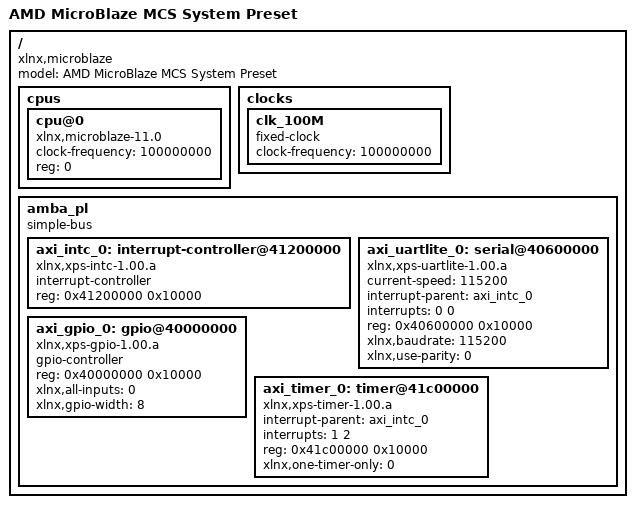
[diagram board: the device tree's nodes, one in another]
/dts-v1/;

/ {
    #address-cells = <1>;
    #size-cells = <1>;
    model = "AMD MicroBlaze MCS System Preset";
    compatible = "xlnx,microblaze";

    cpus {
        #address-cells = <1>;
        #size-cells = <0>;
        cpu@0 {
            clock-frequency = <100000000>;
            compatible = "xlnx,microblaze-11.0";
            device_type = "cpu";
            reg = <0>;
        };
    };

    clocks {
        clk_100M: clk_100M {
            #clock-cells = <0>;
            compatible = "fixed-clock";
            clock-frequency = <100000000>;
        };
    };

    amba_pl: amba_pl {
        #address-cells = <1>;
        #size-cells = <1>;
        compatible = "simple-bus";
        ranges;

        axi_intc_0: interrupt-controller@41200000 {
            #interrupt-cells = <2>;
            compatible = "xlnx,xps-intc-1.00.a";
            interrupt-controller;
            reg = <0x41200000 0x10000>;
        };

        axi_uartlite_0: serial@40600000 {
            compatible = "xlnx,xps-uartlite-1.00.a";
            current-speed = <115200>;
            device_type = "serial";
            interrupt-parent = <&axi_intc_0>;
            interrupts = <0 0>;
            reg = <0x40600000 0x10000>;
            xlnx,baudrate = <115200>;
            xlnx,use-parity = <0>;
        };

        axi_gpio_0: gpio@40000000 {
            #gpio-cells = <2>;
            compatible = "xlnx,xps-gpio-1.00.a";
            gpio-controller;
            reg = <0x40000000 0x10000>;
            xlnx,all-inputs = <0>;
            xlnx,gpio-width = <8>;
        };

        axi_timer_0: timer@41c00000 {
            compatible = "xlnx,xps-timer-1.00.a";
            interrupt-parent = <&axi_intc_0>;
            interrupts = <1 2>;
            reg = <0x41c00000 0x10000>;
            xlnx,one-timer-only = <0>;
        };
    };
};
